VERSION "1"

NS_ :

BS_:

BU_: Ecu1 Ecu2

BO_ 512 MotP: 8 Ecu1
 SG_ P : 7|16@0+ (1,0) [0|65535] "" Ecu2

BO_ 513 MotQ: 8 Ecu1
 SG_ Q : 0|8@0+ (1,0) [0|255] "" Ecu2

BO_ 514 MotS: 8 Ecu1
 SG_ S : 4|20@0+ (1,0) [0|1048575] "" Ecu2

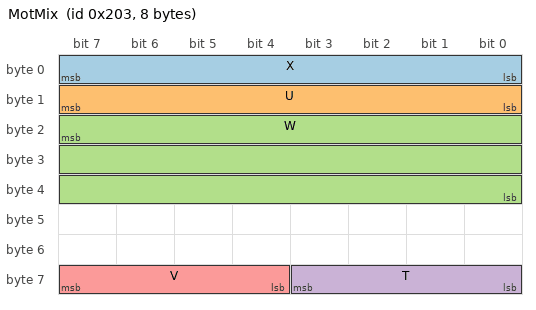
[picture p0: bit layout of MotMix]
BO_ 515 MotMix: 8 Ecu1
 SG_ X : 7|8@0+ (1,0) [0|255] "" Ecu2
 SG_ U : 15|8@0+ (1,0) [0|255] "" Ecu2
 SG_ W : 23|24@0+ (1,0) [0|16777215] "" Ecu2
 SG_ T : 59|4@0+ (1,0) [0|15] "" Ecu2
 SG_ V : 63|4@0+ (1,0) [0|15] "" Ecu2
